# soc-perf-c809403 register map
Vendor: litex
Registers are 32-bit, read-write, reset 0x0 unless marked. A register's access mark holds for its fields unless they carry their own. Offsets are from the block's base; [hi:lo] are bit positions.

## INFO
Base 0xF000A000
0x00 DNA_ID1 — Bits 32-56 of `INFO_DNA_ID`.
  [31:0] dna_id
0x04 DNA_ID0 — Bits 0-31 of `INFO_DNA_ID`.
  [31:0] dna_id
0x08 GIT_MAJOR — Major git tag version. For example, this firmware was built from git tag ``v0.9.10``, so this value is ``0``.
  [7:0] git_major
0x0C GIT_MINOR reset 0x9 — Minor git tag version. For example, this firmware was built from git tag ``v0.9.10``, so this value is ``9``.
  [7:0] git_minor
0x10 GIT_REVISION reset 0xA — Revision git tag version. For example, this firmware was built from git tag ``v0.9.10``, so this value is ``10``.
  [7:0] git_revision
0x14 GIT_GITREV reset 0xC8094038 — First 32-bits of the git revision. This documentation was built from git rev ``c8094038``, so this value is 3356049464, which should be enough to check out the exact git version used to build this firmware.
0x18 GIT_GITEXTRA — The number of additional commits beyond the git tag. For example, if this value is ``1``, then the repository this was built from has one additional commit beyond the tag indicated in `MAJOR`, `MINOR`, and `REVISION`.
  [9:0] git_gitextra
0x1C GIT_DIRTY reset 0x1
  [0] dirty — Set to ``1`` if this device was built from a git repo with uncommitted modifications.
0x20 PLATFORM_PLATFORM1 — Bits 32-63 of `INFO_PLATFORM_PLATFORM`.
  [31:0] platform_platform
0x24 PLATFORM_PLATFORM0 — Bits 0-31 of `INFO_PLATFORM_PLATFORM`.
  [31:0] platform_platform
0x28 PLATFORM_TARGET1 — Bits 32-63 of `INFO_PLATFORM_TARGET`.
  [31:0] platform_target
0x2C PLATFORM_TARGET0 — Bits 0-31 of `INFO_PLATFORM_TARGET`.
  [31:0] platform_target

## SRAM_EXT
Base 0xF000B000
0x00 CONFIG_STATUS
  [31:0] mode — The current configuration mode of the SRAM
0x04 READ_CONFIG
  [0] trigger — Writing to this bit triggers the SRAM mode status read update

## MEMLCD
Base 0xF000C000
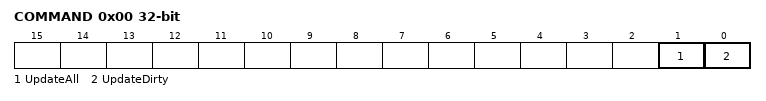
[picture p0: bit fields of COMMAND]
0x00 COMMAND
  [1] UpdateAll — Update full screen regardless of tag state
  [0] UpdateDirty — Write a ``1`` to flush dirty lines to the LCD
0x04 BUSY — A ``1`` indicates that the block is currently updating the LCD
  [0] busy
0x08 PRESCALER reset 0x63 — Prescaler value. LCD clock is module ``(clock / (prescaler+1))``. Reset value: ``99``, so for a default sysclk of 100MHz this yields an LCD ``SCLK`` of 1MHz
  [7:0] prescaler
0x0C EV_STATUS — This register contains the current raw level of the done event trigger. Writes to this register have no effect.
  [0] done — Level of the ``done`` event
0x10 EV_PENDING — When a done event occurs, the corresponding bit will be set in this register. To clear the Event, set the corresponding bit in this register.
  [0] done — `1` if a `done` event occurred. This Event is triggered on a **falling** edge.
0x14 EV_ENABLE — This register enables the corresponding done events. Write a ``0`` to this register to disable individual events.
  [0] done — Write a ``1`` to enable the ``done`` Event
0x18 DEVBOOT
  [0] devboot — When set to ``1``, permanently add a strike-through on the top of the screen. Cannot be cleared, except by a full reset. Do not rely on this register to determine if a devboot has happened; the *register* may be cleared, but the internal hardware bit cannot be.
0x1C DEVSTATUS — Reads back as ``1`` if a devboot was set anywhere along the boot chain. This is a read-only register and reflects ground truth.
  [0] devstatus

## COM
Base 0xF000D000
0x00 TX — Tx data, for COPI. Note: 32-bit CSRs are required for this block to work!
  [15:0] tx
0x04 RX — Rx data, from CIPO
  [15:0] rx
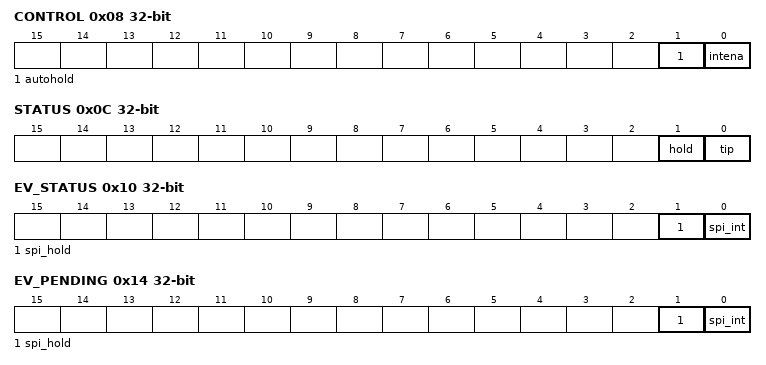
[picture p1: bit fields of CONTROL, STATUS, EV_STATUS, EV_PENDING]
0x08 CONTROL
  [1] autohold — Disallow transmission start if hold if asserted
  [0] intena — Enable interrupt on transaction finished
0x0C STATUS
  [1] hold — Set when peripheral asserts hold
  [0] tip — Set when transaction is in progress
0x10 EV_STATUS — This register contains the current raw level of the spi_hold event trigger. Writes to this register have no effect.
  [1] spi_hold — Level of the ``spi_hold`` event
  [0] spi_int — Level of the ``spi_int`` event
0x14 EV_PENDING — When a spi_hold event occurs, the corresponding bit will be set in this register. To clear the Event, set the corresponding bit in this register.
  [1] spi_hold — `1` if a `spi_hold` event occurred. This Event is triggered on a **falling** edge.
  [0] spi_int — `1` if a `spi_int` event occurred. This Event is triggered on a **falling** edge.
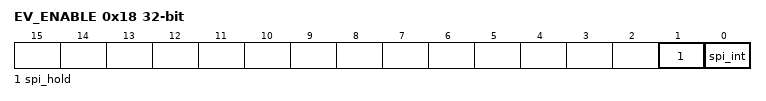
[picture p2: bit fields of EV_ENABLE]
0x18 EV_ENABLE — This register enables the corresponding spi_hold events. Write a ``0`` to this register to disable individual events.
  [1] spi_hold — Write a ``1`` to enable the ``spi_hold`` Event
  [0] spi_int — Write a ``1`` to enable the ``spi_int`` Event
